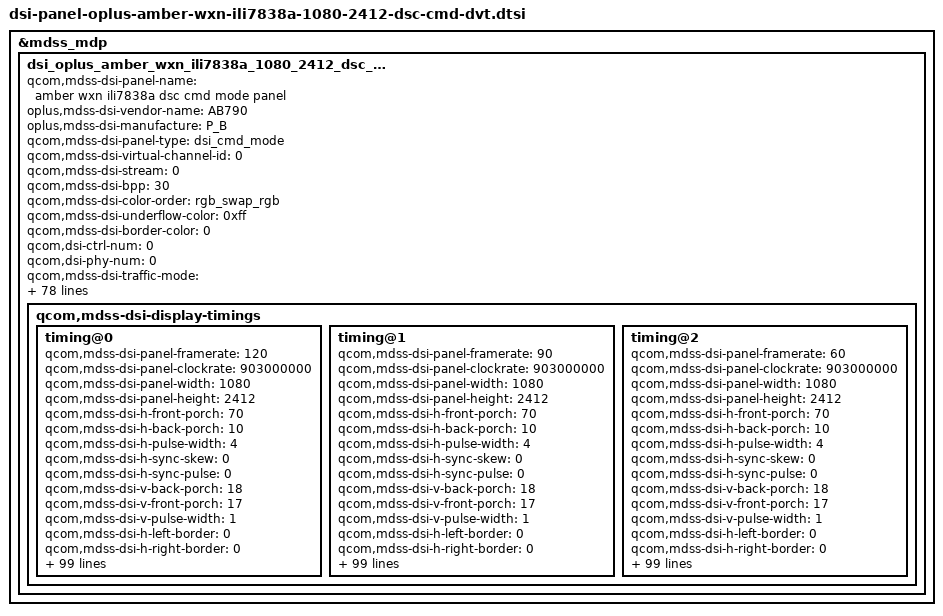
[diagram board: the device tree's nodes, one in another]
&mdss_mdp {
	dsi_oplus_amber_wxn_ili7838a_1080_2412_dsc_cmd_dvt: qcom,mdss_dsi_oplus_amber_wxn_ili7838a_1080_2412_dsc_cmd_dvt {
		qcom,mdss-dsi-panel-name = "amber wxn ili7838a dsc cmd mode panel";
		oplus,mdss-dsi-vendor-name = "AB790";
		oplus,mdss-dsi-manufacture = "P_B";
		qcom,mdss-dsi-panel-type = "dsi_cmd_mode";
		qcom,mdss-dsi-virtual-channel-id = <0>;
		qcom,mdss-dsi-stream = <0>;
		qcom,mdss-dsi-bpp = <30>;
		qcom,mdss-dsi-color-order = "rgb_swap_rgb";
		qcom,mdss-dsi-underflow-color = <0xff>;
		qcom,mdss-dsi-border-color = <0>;
		qcom,dsi-ctrl-num = <0>;
		qcom,dsi-phy-num = <0>;
		qcom,mdss-dsi-traffic-mode = "non_burst_sync_event";
		qcom,mdss-dsi-lane-map = "lane_map_0123";
		qcom,mdss-dsi-bllp-eof-power-mode;
		qcom,mdss-dsi-bllp-power-mode;
		qcom,mdss-dsi-lane-0-state;
		qcom,mdss-dsi-lane-1-state;
		qcom,mdss-dsi-lane-2-state;
		qcom,mdss-dsi-lane-3-state;
		qcom,mdss-dsi-dma-trigger = "trigger_sw";
		qcom,mdss-dsi-mdp-trigger = "none";
		qcom,mdss-dsi-reset-sequence = <1 10>, <0 10>, <1 10>;

		qcom,mdss-dsi-te-pin-select = <1>;
		qcom,mdss-dsi-te-dcs-command = <1>;
		qcom,mdss-dsi-te-check-enable;
		qcom,mdss-dsi-te-using-te-pin;
		qcom,mdss-dsi-lp11-init;
		qcom,mdss-dsi-wr-mem-start = <0x2c>;
		qcom,mdss-dsi-wr-mem-continue = <0x3c>;
		qcom,mdss-dsi-panel-hdr-enabled;
		qcom,mdss-dsi-panel-hdr-color-primaries = <15635 16450 34000 16000 13250 34500 7500 3000>;
		qcom,mdss-dsi-panel-peak-brightness = <5400000>;
		qcom,mdss-dsi-panel-blackness-level = <2000>;
		qcom,mdss-pan-physical-width-dimension = <70>;
		qcom,mdss-pan-physical-height-dimension = <155>;
		qcom,esd-check-enabled;
		qcom,mdss-dsi-panel-status-check-mode = "reg_read";
		qcom,mdss-dsi-panel-status-command = [06 01 00 01 05 00 01 0A];
		qcom,mdss-dsi-panel-status-command-state = "dsi_lp_mode";
		qcom,mdss-dsi-panel-status-value = <0x9C>;
		qcom,mdss-dsi-panel-status-read-length = <1>;
		qcom,mdss-dsi-dma-schedule-line = <1>;
		qcom,mdss-dsi-dma-schedule-window = <10>;
		qcom,mdss-dsi-display-timings {
			timing@0 {
				qcom,mdss-dsi-panel-framerate = <120>;
				qcom,mdss-dsi-panel-clockrate = <903000000>;
				qcom,mdss-dsi-panel-width = <1080>;
				qcom,mdss-dsi-panel-height = <2412>;
				qcom,mdss-dsi-h-front-porch = <70>;
				qcom,mdss-dsi-h-back-porch = <10>;
				qcom,mdss-dsi-h-pulse-width = <4>;
				qcom,mdss-dsi-h-sync-skew = <0>;
				qcom,mdss-dsi-h-sync-pulse = <0>;
				qcom,mdss-dsi-v-back-porch = <18>;
				qcom,mdss-dsi-v-front-porch = <17>;
				qcom,mdss-dsi-v-pulse-width = <1>;
				qcom,mdss-dsi-h-left-border = <0>;
				qcom,mdss-dsi-h-right-border = <0>;
				qcom,mdss-dsi-v-top-border = <0>;
				qcom,mdss-dsi-v-bottom-border = <0>;
				qcom,mdss-dsi-panel-jitter = <0x4 0x1>;
				qcom,mdss-mdp-transfer-time-us = <6727>;

				oplus,fod-on-vblank = <0>;
				oplus,fod-off-vblank = <0>;
				oplus,ofp-need-to-sync-data-in-aod-unlocking;
				oplus,ofp-aod-off-insert-black-frame = <1>;
				oplus,ofp-aod-off-black-frame-total-time = <42>;

				qcom,mdss-dsi-timing-switch-command = [
					//120HZ
					39 00 00 40 00 00 04 FF 78 38 02
					39 00 00 40 00 00 02 38 11
					39 00 00 00 00 00 04 FF 78 38 00
				];
				qcom,mdss-dsi-on-command = [
					39 01 00 00 00 00 04 FF 78 38 08
					39 01 00 00 00 00 02 45 4C
					39 01 00 00 00 00 04 FF 78 38 02
					39 01 00 00 00 00 02 38 11
					39 01 00 00 00 00 04 FF 78 38 00
					39 01 00 00 00 00 02 35 00
					39 01 00 00 00 00 02 53 20
					39 01 00 00 00 00 03 51 00 00
					39 01 00 00 00 00 02 95 10
					39 01 00 00 00 00 04 FF 78 38 00
					//dsc 10bit
					39 01 00 00 00 00 04 FF 78 38 07
					39 01 00 00 00 00 02 29 01
					39 01 00 00 00 00 64 20 00 00 00
						00 00 12 00 00 ab 30 a0 09 6c 04
						38 00 0c 02 1c 02 a3 01 9a 01 d8
						00 19 01 03 00 0a 00 0c 08 bb 0a
						5f 16 00 10 ec 07 10 20 00 06 0f
						0f 33 0e 1c 2a 38 46 54 62 69 70
						77 79 7b 7d 7e 01 c2 22 00 2a 40
						32 be 3a fc 3a fa 3a f8 3b 38 3b
						78 3b 76 4b b6 4b b6 4b f4 5b f4
						7c 34 00 00 00 00 00 00
					39 01 00 00 00 00 04 FF 78 38 07
					39 01 00 00 00 00 64 1F 00 00 00
						00 00 12 00 00 ab 30 a0 09 6c 04
						38 00 0c 02 1c 02 a3 01 9a 01 d8
						00 19 01 03 00 0a 00 0c 08 bb 0a
						5f 16 00 10 ec 07 10 20 00 06 0f
						0f 33 0e 1c 2a 38 46 54 62 69 70
						77 79 7b 7d 7e 01 c2 22 00 2a 40
						32 be 3a fc 3a fa 3a f8 3b 38 3b
						78 3b 76 4b b6 4b b6 4b f4 5b f4
						7c 34 00 00 00 00 00 00
					//lvd
					39 01 00 00 00 00 04 FF 78 38 1C
					39 01 00 00 00 00 02 78 10
					39 01 00 00 00 00 02 6A FF
					39 01 00 00 00 00 02 6E FF
					39 01 00 00 00 00 04 FF 78 38 02
					39 01 00 00 00 00 02 0A 20
					39 01 00 00 00 00 04 FF 78 38 05
					39 01 00 00 00 00 02 01 50
					39 01 00 00 00 00 02 1D DF
					39 01 00 00 00 00 02 1E 07
					//Sleep out
					39 00 00 40 00 00 04 FF 78 38 07
					15 00 00 40 00 00 02 2B 24
					39 01 00 00 00 00 04 FF 78 38 00
					05 01 00 00 79 00 01 11
					39 01 00 00 00 00 04 FF 78 38 05
					39 01 00 00 00 00 02 5B 42
					39 01 00 00 00 00 04 FF 78 38 08
					39 01 00 00 00 00 02 57 25
					39 01 00 00 00 00 04 FF 78 38 06
					39 01 00 00 00 00 02 C6 01
					39 01 00 00 00 00 04 FF 78 38 00
					05 01 00 00 46 00 01 29
				];
				qcom,mdss-dsi-off-command= [
					05 01 00 00 15 00 01 28
					05 01 00 00 79 00 01 10
				];
				qcom,mdss-dsi-post-on-backlight = [
					/* Display On */
					//39 00 00 40 00 00 04 FF 78 38 00
					//05 00 00 00 00 00 01 39
				];
				qcom,mdss-dsi-panel-info-switch-page-command = [
					/*read panel info switch page 0f*/
					39 00 00 00 00 00 04 FF 78 38 0F
				];
				qcom,mdss-dsi-default-switch-page-command = [
					/*switch default page*/
					39 00 00 00 00 00 04 FF 78 38 00
				];
				qcom,mdss-dsi-hbm-on-command = [
					//hbm
					39 00 00 40 00 00 04 FF 78 38 0B
					39 00 00 40 00 00 02 17 E2
					39 00 00 40 00 00 02 18 E2
					39 00 00 40 00 00 02 19 E2
					39 00 00 40 00 00 02 1A E2
					39 00 00 40 00 00 02 1B E2
					39 00 00 40 00 00 02 1C E2
					39 00 00 40 00 00 02 1D E2
					39 00 00 40 00 00 04 FF 78 38 0A
					39 00 00 40 00 00 02 37 4F
					39 00 00 40 00 00 02 38 B4
					39 00 00 40 00 00 04 FF 78 38 00
					39 00 00 40 00 00 02 55 00
					39 00 00 40 00 00 04 FF 78 38 05
					39 00 00 40 00 00 02 4F 24
					39 00 00 40 00 00 04 FF 78 38 00
					39 00 00 40 09 00 02 53 20
					39 00 00 40 00 00 03 51 0E 4C
					39 00 00 00 00 00 04 FF 78 38 00
				];
				qcom,mdss-dsi-normal-hbm-on-command = [
					//hbm
				];
				qcom,mdss-dsi-hbm-off-command = [
					39 00 00 40 00 00 04 FF 78 38 0A
					39 00 00 40 00 00 02 37 4F
					39 00 00 40 00 00 02 38 48
					39 00 00 40 00 00 04 FF 78 38 00
					39 00 00 40 00 00 02 55 00
					39 00 00 40 00 00 03 51 0D BB
					39 00 00 40 00 00 04 FF 78 38 00
					39 00 00 40 00 00 04 FF 78 38 05
					39 00 00 40 00 00 02 4F 2C
					39 00 00 00 00 00 04 FF 78 38 00
				];
				qcom,mdss-dsi-lhbm-on-command = [
					39 00 00 60 00 00 04 FF 78 38 05
					15 00 00 60 00 00 02 5D 1E
					39 00 00 60 00 00 04 FF 78 38 0D
					15 00 00 60 00 00 02 08 51
					15 00 00 60 00 00 02 65 2D
					15 00 00 60 00 00 02 47 E9
					15 00 00 60 00 00 02 48 E9
					15 00 00 60 00 00 02 49 E9
					39 00 00 60 00 00 04 FF 78 38 0C
					15 00 00 60 00 00 02 AB AB
					39 00 00 60 00 00 04 FF 78 38 00
					15 00 00 60 00 00 02 95 11
					39 00 00 60 00 00 04 FF 78 38 0A
					15 00 00 60 00 00 02 1C 11
					15 00 00 60 00 00 02 1D 8A
					15 00 00 60 00 00 02 1E 8A
					39 00 00 20 00 00 04 FF 78 38 00
				];
				qcom,mdss-dsi-lhbm-on2-command = [
					39 00 00 60 00 00 04 FF 78 38 0A
					15 00 00 60 00 00 02 1C 88
					15 00 00 60 00 00 02 1D 00
					15 00 00 60 00 00 02 1E 00
					39 00 00 20 00 00 04 FF 78 38 00
				];
				qcom,mdss-dsi-lhbm-off-command = [
					39 00 00 60 00 00 04 FF 78 38 0D
					15 00 00 60 00 00 02 08 D1
					15 00 00 60 00 00 02 65 00
					39 00 00 60 00 00 04 FF 78 38 05
					15 00 00 60 00 00 02 5D 42
					39 00 00 60 00 00 04 FF 78 38 00
					15 00 00 60 00 00 02 95 10
					39 00 00 60 00 00 04 FF 78 38 0A
					15 00 00 60 00 00 02 1C 88
					15 00 00 60 00 00 02 1D 00
					15 00 00 60 00 00 02 1E 00
					15 00 00 60 00 00 02 1F 88
					15 00 00 60 00 00 02 20 00
					15 00 00 60 00 00 02 21 00
					15 00 00 60 00 00 02 22 88
					15 00 00 60 00 00 02 23 00
					15 00 00 60 00 00 02 24 00
					39 00 00 20 00 00 04 FF 78 38 00
				];
				qcom,mdss-dsi-lhbm-off2-command = [
					39 00 00 60 00 00 04 FF 78 38 0A
					15 00 00 60 00 00 02 1C 88
					15 00 00 60 00 00 02 1D 00
					15 00 00 60 00 00 02 1E 00
					15 00 00 60 00 00 02 1F 40
					15 00 00 60 00 00 02 20 00
					15 00 00 60 00 00 02 21 77
					15 00 00 60 00 00 02 22 00
					15 00 00 60 00 00 02 23 03
					15 00 00 60 00 00 02 24 00
					39 00 00 20 00 00 04 FF 78 38 00
				];
				qcom,mdss-dsi-aod-hbm-on-command = [

				];
				qcom,mdss-dsi-aod-hbm-off-command = [

				];
				qcom,mdss-dsi-aod-high-mode-command = [
					39 00 00 40 00 00 04 FF 78 38 02
					15 00 00 40 00 00 02 38 11
					15 00 00 40 00 00 02 19 02
					39 00 00 40 00 00 04 FF 78 38 00
					05 00 00 00 00 00 01 39
				];
				qcom,mdss-dsi-aod-low-mode-command = [
					39 00 00 40 00 00 04 FF 78 38 02
					15 00 00 40 00 00 02 38 21
					15 00 00 40 00 00 02 19 01
					39 00 00 40 00 00 04 FF 78 38 00
					05 00 00 00 00 00 01 39
				];
				qcom,mdss-dsi-lp1-command = [
					//AOD ON
					39 00 00 40 00 00 04 FF 78 38 02
					15 00 00 40 00 00 02 38 11
					15 00 00 40 00 00 02 19 02
					39 00 00 40 00 00 04 FF 78 38 00
					05 00 00 00 00 00 01 39
				];
				qcom,mdss-dsi-nolp-command = [
					//AOD OFF
					39 00 00 40 00 00 04 FF 78 38 00
					05 00 00 40 00 00 01 38
					39 00 00 40 00 00 03 51 00 00
					39 01 00 40 00 00 04 FF 78 38 05
					39 01 00 40 00 00 02 5B 42
					39 00 00 00 00 00 04 FF 78 38 00
				];
				//qcom,mdss-dsi-seed-off-command = [

				//];
				//qcom,mdss-dsi-seed-3-command = [

				//];
				//qcom,mdss-dsi-seed-2-command = [

				//];
				//qcom,mdss-dsi-seed-1-command = [

				//];
				//qcom,mdss-dsi-seed-0-command = [

				//];
				qcom,mdss-dsi-hbm-enter-switch-command = [
					39 00 00 00 00 00 03 51 0D BB
				];
				qcom,mdss-dsi-hbm-exit-switch-command = [
					39 00 00 00 00 00 03 51 0D BB
				];
				qcom,mdss-dsi-osc-clk-mode0-command = [
				];
				qcom,mdss-dsi-osc-clk-mode1-command = [
				];
				qcom,mdss-dsi-ffc-mode0-command = [
					/* osc 121.5 */
					39 00 00 40 00 00 04 FF 78 38 0F
					39 00 00 40 00 00 02 6E 12
					39 00 00 00 00 00 04 FF 78 38 00
				];
				qcom,mdss-dsi-ffc-mode1-command = [
					/* osc 128 */
					39 00 00 40 00 00 04 FF 78 38 0F
					39 00 00 40 00 00 02 6E 13
					39 00 00 00 00 00 04 FF 78 38 00
				];
				qcom,mdss-dsi-timing-switch-command-state = "dsi_lp_mode";
				qcom,mdss-dsi-on-command-state = "dsi_lp_mode";
				qcom,mdss-dsi-panel-info-switch-page-command-state = "dsi_lp_mode";
				qcom,mdss-dsi-default-switch-page-command-state = "dsi_lp_mode";
				qcom,mdss-dsi-off-command-state = "dsi_lp_mode";
				qcom,mdss-dsi-hbm-on-command-state = "dsi_lp_mode";
				qcom,mdss-dsi-hbm-off-command-state = "dsi_lp_mode";
				qcom,mdss-dsi-lhbm-on-command-state = "dsi_hs_mode";
				qcom,mdss-dsi-lhbm-off-command-state = "dsi_hs_mode";
				qcom,mdss-dsi-lhbm-on2-command-state = "dsi_hs_mode";
				qcom,mdss-dsi-lhbm-off2-command-state = "dsi_hs_mode";
				qcom,mdss-dsi-lp1-command-state = "dsi_lp_mode";
				qcom,mdss-dsi-nolp-command-state = "dsi_lp_mode";
				qcom,mdss-dsi-aod-high-mode-command-state = "dsi_lp_mode";
				qcom,mdss-dsi-aod-low-mode-command-state = "dsi_lp_mode";
				qcom,mdss-dsi-osc-clk-mode0-command-state = "dsi_lp_mode";
				qcom,mdss-dsi-osc-clk-mode1-command-state = "dsi_lp_mode";
				qcom,mdss-dsi-ffc-mode0-command-state = "dsi_lp_mode";
				qcom,mdss-dsi-ffc-mode1-command-state = "dsi_lp_mode";
				//qcom,mdss-dsi-seed-0-command-state = "dsi_lp_mode";
				//qcom,mdss-dsi-seed-1-command-state = "dsi_lp_mode";
				//qcom,mdss-dsi-seed-2-command-state = "dsi_lp_mode";
				//qcom,mdss-dsi-seed-3-command-state = "dsi_lp_mode";
				//qcom,mdss-dsi-seed-off-command-state = "dsi_lp_mode";
				qcom,compression-mode = "dsc";
				qcom,mdss-dsc-slice-height = <12>;
				qcom,mdss-dsc-slice-width = <540>;
				qcom,mdss-dsc-slice-per-pkt = <2>;
				qcom,mdss-dsc-bit-per-component = <10>;
				qcom,mdss-dsc-bit-per-pixel = <10>;
				qcom,mdss-dsc-block-prediction-enable;
				qcom,mdss-dsc-version = <0x12>;
			};
			timing@1 {
				qcom,mdss-dsi-panel-framerate = <90>;
				qcom,mdss-dsi-panel-clockrate = <903000000>;
				qcom,mdss-dsi-panel-width = <1080>;
				qcom,mdss-dsi-panel-height = <2412>;
				qcom,mdss-dsi-h-front-porch = <70>;
				qcom,mdss-dsi-h-back-porch = <10>;
				qcom,mdss-dsi-h-pulse-width = <4>;
				qcom,mdss-dsi-h-sync-skew = <0>;
				qcom,mdss-dsi-h-sync-pulse = <0>;
				qcom,mdss-dsi-v-back-porch = <18>;
				qcom,mdss-dsi-v-front-porch = <17>;
				qcom,mdss-dsi-v-pulse-width = <1>;
				qcom,mdss-dsi-h-left-border = <0>;
				qcom,mdss-dsi-h-right-border = <0>;
				qcom,mdss-dsi-v-top-border = <0>;
				qcom,mdss-dsi-v-bottom-border = <0>;
				qcom,mdss-dsi-panel-jitter = <0x4 0x1>;
				qcom,mdss-mdp-transfer-time-us = <9000>;

				oplus,fod-on-vblank = <0>;
				oplus,fod-off-vblank = <0>;
				oplus,ofp-need-to-sync-data-in-aod-unlocking;
				oplus,ofp-aod-off-insert-black-frame = <1>;
				oplus,ofp-aod-off-black-frame-total-time = <45>;
				qcom,mdss-dsi-timing-switch-command = [
					//90HZ
					39 00 00 40 00 00 04 FF 78 38 02
					39 00 00 40 00 00 02 38 12
					39 00 00 00 00 00 04 FF 78 38 00
				];
				qcom,mdss-dsi-on-command = [
					39 01 00 00 00 00 04 FF 78 38 08
					39 01 00 00 00 00 02 45 4C
					39 01 00 00 00 00 04 FF 78 38 02
					39 01 00 00 00 00 02 38 12
					39 01 00 00 00 00 04 FF 78 38 00
					39 01 00 00 00 00 02 35 00
					39 01 00 00 00 00 02 53 20
					39 01 00 00 00 00 03 51 00 00
					39 01 00 00 00 00 02 95 10
					39 01 00 00 00 00 04 FF 78 38 00
					//dsc 10bit
					39 01 00 00 00 00 04 FF 78 38 07
					39 01 00 00 00 00 02 29 01
					39 01 00 00 00 00 64 20 00 00 00
						00 00 12 00 00 ab 30 a0 09 6c 04
						38 00 0c 02 1c 02 a3 01 9a 01 d8
						00 19 01 03 00 0a 00 0c 08 bb 0a
						5f 16 00 10 ec 07 10 20 00 06 0f
						0f 33 0e 1c 2a 38 46 54 62 69 70
						77 79 7b 7d 7e 01 c2 22 00 2a 40
						32 be 3a fc 3a fa 3a f8 3b 38 3b
						78 3b 76 4b b6 4b b6 4b f4 5b f4
						7c 34 00 00 00 00 00 00
					39 01 00 00 00 00 04 FF 78 38 07
					39 01 00 00 00 00 64 1F 00 00 00
						00 00 12 00 00 ab 30 a0 09 6c 04
						38 00 0c 02 1c 02 a3 01 9a 01 d8
						00 19 01 03 00 0a 00 0c 08 bb 0a
						5f 16 00 10 ec 07 10 20 00 06 0f
						0f 33 0e 1c 2a 38 46 54 62 69 70
						77 79 7b 7d 7e 01 c2 22 00 2a 40
						32 be 3a fc 3a fa 3a f8 3b 38 3b
						78 3b 76 4b b6 4b b6 4b f4 5b f4
						7c 34 00 00 00 00 00 00
					//lvd
					39 01 00 00 00 00 04 FF 78 38 1C
					39 01 00 00 00 00 02 78 10
					39 01 00 00 00 00 02 6A FF
					39 01 00 00 00 00 02 6E FF
					39 01 00 00 00 00 04 FF 78 38 02
					39 01 00 00 00 00 02 0A 20
					39 01 00 00 00 00 04 FF 78 38 05
					39 01 00 00 00 00 02 01 50
					39 01 00 00 00 00 02 1D DF
					39 01 00 00 00 00 02 1E 07
					//Sleep out
					39 00 00 40 00 00 04 FF 78 38 07
					15 00 00 40 00 00 02 2B 24
					39 01 00 00 00 00 04 FF 78 38 00
					05 01 00 00 79 00 01 11
					39 01 00 00 00 00 04 FF 78 38 05
					39 01 00 00 00 00 02 5B 42
					39 01 00 00 00 00 04 FF 78 38 08
					39 01 00 00 00 00 02 57 25
					39 01 00 00 00 00 04 FF 78 38 06
					39 01 00 00 00 00 02 C6 01
					39 01 00 00 00 00 04 FF 78 38 00
					05 01 00 00 46 00 01 29
				];
				qcom,mdss-dsi-off-command= [
					05 01 00 00 15 00 01 28
					05 01 00 00 79 00 01 10
				];
				qcom,mdss-dsi-post-on-backlight = [
					/* Display On */
					//39 00 00 40 00 00 04 FF 78 38 00
					//05 00 00 00 00 00 01 39
				];
				qcom,mdss-dsi-panel-info-switch-page-command = [
					/*read panel info switch page 0f*/
					39 00 00 00 00 00 04 FF 78 38 0F
				];
				qcom,mdss-dsi-default-switch-page-command = [
					/*switch default page*/
					39 00 00 00 00 00 04 FF 78 38 00
				];
				qcom,mdss-dsi-hbm-on-command = [
					//hbm
					39 00 00 40 00 00 04 FF 78 38 0B
					39 00 00 40 00 00 02 17 E2
					39 00 00 40 00 00 02 18 E2
					39 00 00 40 00 00 02 19 E2
					39 00 00 40 00 00 02 1A E2
					39 00 00 40 00 00 02 1B E2
					39 00 00 40 00 00 02 1C E2
					39 00 00 40 00 00 02 1D E2
					39 00 00 40 00 00 04 FF 78 38 0A
					39 00 00 40 00 00 02 37 4F
					39 00 00 40 00 00 02 38 B4
					39 00 00 40 00 00 04 FF 78 38 00
					39 00 00 40 00 00 02 55 00
					39 00 00 40 00 00 04 FF 78 38 05
					39 00 00 40 00 00 02 4F 24
					39 00 00 40 00 00 04 FF 78 38 00
					39 00 00 40 0C 00 02 53 20
					39 00 00 40 00 00 03 51 0E 4C
					39 00 00 00 00 00 04 FF 78 38 00
				];
				qcom,mdss-dsi-normal-hbm-on-command = [
					//hbm
				];
				qcom,mdss-dsi-hbm-off-command = [
					39 00 00 40 00 00 04 FF 78 38 0A
					39 00 00 40 00 00 02 37 4F
					39 00 00 40 00 00 02 38 48
					39 00 00 40 00 00 04 FF 78 38 00
					39 00 00 40 00 00 02 55 00
					39 00 00 40 00 00 03 51 0D BB
					39 00 00 40 00 00 04 FF 78 38 00
					39 00 00 40 00 00 04 FF 78 38 05
					39 00 00 40 00 00 02 4F 2C
					39 00 00 00 00 00 04 FF 78 38 00
				];
				qcom,mdss-dsi-lhbm-on-command = [
					39 00 00 60 00 00 04 FF 78 38 05
					15 00 00 60 00 00 02 5D 1E
					39 00 00 60 00 00 04 FF 78 38 0D
					15 00 00 60 00 00 02 08 51
					15 00 00 60 00 00 02 65 2D
					15 00 00 60 00 00 02 47 E9
					15 00 00 60 00 00 02 48 E9
					15 00 00 60 00 00 02 49 E9
					39 00 00 60 00 00 04 FF 78 38 0C
					15 00 00 60 00 00 02 AB AB
					39 00 00 60 00 00 04 FF 78 38 00
					15 00 00 60 00 00 02 95 11
					39 00 00 60 00 00 04 FF 78 38 0A
					15 00 00 60 00 00 02 1C 11
					15 00 00 60 00 00 02 1D 8A
					15 00 00 60 00 00 02 1E 8A
					39 00 00 20 00 00 04 FF 78 38 00
				];
				qcom,mdss-dsi-lhbm-on2-command = [
					39 00 00 60 00 00 04 FF 78 38 0A
					15 00 00 60 00 00 02 1C 88
					15 00 00 60 00 00 02 1D 00
					15 00 00 60 00 00 02 1E 00
					39 00 00 20 00 00 04 FF 78 38 00
				];
				qcom,mdss-dsi-lhbm-off-command = [
					39 00 00 60 00 00 04 FF 78 38 0D
					15 00 00 60 00 00 02 08 D1
					15 00 00 60 00 00 02 65 00
					39 00 00 60 00 00 04 FF 78 38 05
					15 00 00 60 00 00 02 5D 42
					39 00 00 60 00 00 04 FF 78 38 00
					15 00 00 60 00 00 02 95 10
					39 00 00 60 00 00 04 FF 78 38 0A
					15 00 00 60 00 00 02 1C 88
					15 00 00 60 00 00 02 1D 00
					15 00 00 60 00 00 02 1E 00
					15 00 00 60 00 00 02 1F 88
					15 00 00 60 00 00 02 20 00
					15 00 00 60 00 00 02 21 00
					15 00 00 60 00 00 02 22 88
					15 00 00 60 00 00 02 23 00
					15 00 00 60 00 00 02 24 00
					39 00 00 20 00 00 04 FF 78 38 00
				];
				qcom,mdss-dsi-lhbm-off2-command = [
					39 00 00 60 00 00 04 FF 78 38 0A
					15 00 00 60 00 00 02 1C 88
					15 00 00 60 00 00 02 1D 00
					15 00 00 60 00 00 02 1E 00
					15 00 00 60 00 00 02 1F 40
					15 00 00 60 00 00 02 20 00
					15 00 00 60 00 00 02 21 77
					15 00 00 60 00 00 02 22 00
					15 00 00 60 00 00 02 23 03
					15 00 00 60 00 00 02 24 00
					39 00 00 20 00 00 04 FF 78 38 00
				];
				qcom,mdss-dsi-aod-hbm-on-command = [

				];
				qcom,mdss-dsi-aod-hbm-off-command = [

				];
				qcom,mdss-dsi-aod-high-mode-command = [
					39 00 00 40 00 00 04 FF 78 38 02
					15 00 00 40 00 00 02 38 12
					15 00 00 40 00 00 02 19 02
					39 00 00 40 00 00 04 FF 78 38 00
					05 00 00 00 00 00 01 39
				];
				qcom,mdss-dsi-aod-low-mode-command = [
					39 00 00 40 00 00 04 FF 78 38 02
					15 00 00 40 00 00 02 38 22
					15 00 00 40 00 00 02 19 01
					39 00 00 40 00 00 04 FF 78 38 00
					05 00 00 00 00 00 01 39
				];
				qcom,mdss-dsi-lp1-command = [
					//AOD ON
					39 00 00 40 00 00 04 FF 78 38 02
					15 00 00 40 00 00 02 38 12
					15 00 00 40 00 00 02 19 02
					39 00 00 40 00 00 04 FF 78 38 00
					05 00 00 00 00 00 01 39
				];
				qcom,mdss-dsi-nolp-command = [
					//AOD OFF
					39 00 00 40 00 00 04 FF 78 38 00
					05 00 00 40 00 00 01 38
					39 00 00 40 00 00 03 51 00 00
					39 01 00 40 00 00 04 FF 78 38 05
					39 01 00 40 00 00 02 5B 42
					39 00 00 00 00 00 04 FF 78 38 00
				];
				//qcom,mdss-dsi-seed-off-command = [

				//];
				//qcom,mdss-dsi-seed-3-command = [

				//];
				//qcom,mdss-dsi-seed-2-command = [

				//];
				//qcom,mdss-dsi-seed-1-command = [

				//];
				//qcom,mdss-dsi-seed-0-command = [

				//];
				qcom,mdss-dsi-hbm-enter-switch-command = [
					39 00 00 00 00 00 03 51 0D BB
				];
				qcom,mdss-dsi-hbm-exit-switch-command = [
					39 00 00 00 00 00 03 51 0D BB
				];
				qcom,mdss-dsi-osc-clk-mode0-command = [
				];
				qcom,mdss-dsi-osc-clk-mode1-command = [
				];
				qcom,mdss-dsi-ffc-mode0-command = [
					/* osc 121.5 */
					39 00 00 40 00 00 04 FF 78 38 0F
					39 00 00 40 00 00 02 6E 12
					39 00 00 00 00 00 04 FF 78 38 00
				];
				qcom,mdss-dsi-ffc-mode1-command = [
					/* osc 128 */
					39 00 00 40 00 00 04 FF 78 38 0F
					39 00 00 40 00 00 02 6E 13
					39 00 00 00 00 00 04 FF 78 38 00
				];
				qcom,mdss-dsi-timing-switch-command-state = "dsi_lp_mode";
				qcom,mdss-dsi-on-command-state = "dsi_lp_mode";
				qcom,mdss-dsi-panel-info-switch-page-command-state = "dsi_lp_mode";
				qcom,mdss-dsi-default-switch-page-command-state = "dsi_lp_mode";
				qcom,mdss-dsi-off-command-state = "dsi_lp_mode";
				qcom,mdss-dsi-hbm-on-command-state = "dsi_lp_mode";
				qcom,mdss-dsi-hbm-off-command-state = "dsi_lp_mode";
				qcom,mdss-dsi-lhbm-on-command-state = "dsi_hs_mode";
				qcom,mdss-dsi-lhbm-off-command-state = "dsi_hs_mode";
				qcom,mdss-dsi-lhbm-on2-command-state = "dsi_hs_mode";
				qcom,mdss-dsi-lhbm-off2-command-state = "dsi_hs_mode";
				qcom,mdss-dsi-lp1-command-state = "dsi_lp_mode";
				qcom,mdss-dsi-nolp-command-state = "dsi_lp_mode";
				qcom,mdss-dsi-aod-high-mode-command-state = "dsi_lp_mode";
				qcom,mdss-dsi-aod-low-mode-command-state = "dsi_lp_mode";
				qcom,mdss-dsi-osc-clk-mode0-command-state = "dsi_lp_mode";
				qcom,mdss-dsi-osc-clk-mode1-command-state = "dsi_lp_mode";
				qcom,mdss-dsi-ffc-mode0-command-state = "dsi_lp_mode";
				qcom,mdss-dsi-ffc-mode1-command-state = "dsi_lp_mode";
				//qcom,mdss-dsi-seed-0-command-state = "dsi_lp_mode";
				//qcom,mdss-dsi-seed-1-command-state = "dsi_lp_mode";
				//qcom,mdss-dsi-seed-2-command-state = "dsi_lp_mode";
				//qcom,mdss-dsi-seed-3-command-state = "dsi_lp_mode";
				//qcom,mdss-dsi-seed-off-command-state = "dsi_lp_mode";
				qcom,compression-mode = "dsc";
				qcom,mdss-dsc-slice-height = <12>;
				qcom,mdss-dsc-slice-width = <540>;
				qcom,mdss-dsc-slice-per-pkt = <2>;
				qcom,mdss-dsc-bit-per-component = <10>;
				qcom,mdss-dsc-bit-per-pixel = <10>;
				qcom,mdss-dsc-block-prediction-enable;
				qcom,mdss-dsc-version = <0x12>;
			};
			timing@2 {
				qcom,mdss-dsi-panel-framerate = <60>;
				qcom,mdss-dsi-panel-clockrate = <903000000>;
				qcom,mdss-dsi-panel-width = <1080>;
				qcom,mdss-dsi-panel-height = <2412>;
				qcom,mdss-dsi-h-front-porch = <70>;
				qcom,mdss-dsi-h-back-porch = <10>;
				qcom,mdss-dsi-h-pulse-width = <4>;
				qcom,mdss-dsi-h-sync-skew = <0>;
				qcom,mdss-dsi-h-sync-pulse = <0>;
				qcom,mdss-dsi-v-back-porch = <18>;
				qcom,mdss-dsi-v-front-porch = <17>;
				qcom,mdss-dsi-v-pulse-width = <1>;
				qcom,mdss-dsi-h-left-border = <0>;
				qcom,mdss-dsi-h-right-border = <0>;
				qcom,mdss-dsi-v-top-border = <0>;
				qcom,mdss-dsi-v-bottom-border = <0>;
				qcom,mdss-dsi-panel-jitter = <0x4 0x1>;
				qcom,mdss-mdp-transfer-time-us = <12000>;

				oplus,fod-on-vblank = <0>;
				oplus,fod-off-vblank = <0>;
				oplus,ofp-need-to-sync-data-in-aod-unlocking;
				oplus,ofp-aod-off-insert-black-frame = <2>;
				oplus,ofp-aod-off-black-frame-total-time = <59>;

				qcom,mdss-dsi-timing-switch-command = [
					//60HZ
					39 00 00 40 00 00 04 FF 78 38 02
					39 00 00 40 00 00 02 38 13
					39 00 00 00 00 00 04 FF 78 38 00
				];
				qcom,mdss-dsi-on-command = [
					39 01 00 00 00 00 04 FF 78 38 08
					39 01 00 00 00 00 02 45 4C
					39 01 00 00 00 00 04 FF 78 38 02
					39 01 00 00 00 00 02 38 13
					39 01 00 00 00 00 04 FF 78 38 00
					39 01 00 00 00 00 02 35 00
					39 01 00 00 00 00 02 53 20
					39 01 00 00 00 00 03 51 00 00
					39 01 00 00 00 00 02 95 10
					39 01 00 00 00 00 04 FF 78 38 00
					//dsc 10bit
					39 01 00 00 00 00 04 FF 78 38 07
					39 01 00 00 00 00 02 29 01
					39 01 00 00 00 00 64 20 00 00 00
						00 00 12 00 00 ab 30 a0 09 6c 04
						38 00 0c 02 1c 02 a3 01 9a 01 d8
						00 19 01 03 00 0a 00 0c 08 bb 0a
						5f 16 00 10 ec 07 10 20 00 06 0f
						0f 33 0e 1c 2a 38 46 54 62 69 70
						77 79 7b 7d 7e 01 c2 22 00 2a 40
						32 be 3a fc 3a fa 3a f8 3b 38 3b
						78 3b 76 4b b6 4b b6 4b f4 5b f4
						7c 34 00 00 00 00 00 00
					39 01 00 00 00 00 04 FF 78 38 07
					39 01 00 00 00 00 64 1F 00 00 00
						00 00 12 00 00 ab 30 a0 09 6c 04
						38 00 0c 02 1c 02 a3 01 9a 01 d8
						00 19 01 03 00 0a 00 0c 08 bb 0a
						5f 16 00 10 ec 07 10 20 00 06 0f
						0f 33 0e 1c 2a 38 46 54 62 69 70
						77 79 7b 7d 7e 01 c2 22 00 2a 40
						32 be 3a fc 3a fa 3a f8 3b 38 3b
						78 3b 76 4b b6 4b b6 4b f4 5b f4
						7c 34 00 00 00 00 00 00
					//lvd
					39 01 00 00 00 00 04 FF 78 38 1C
					39 01 00 00 00 00 02 78 10
					39 01 00 00 00 00 02 6A FF
					39 01 00 00 00 00 02 6E FF
					39 01 00 00 00 00 04 FF 78 38 02
					39 01 00 00 00 00 02 0A 20
					39 01 00 00 00 00 04 FF 78 38 05
					39 01 00 00 00 00 02 01 50
					39 01 00 00 00 00 02 1D DF
					39 01 00 00 00 00 02 1E 07
					//Sleep out
					39 00 00 40 00 00 04 FF 78 38 07
					15 00 00 40 00 00 02 2B 24
					39 01 00 00 00 00 04 FF 78 38 00
					05 01 00 00 79 00 01 11
					39 01 00 00 00 00 04 FF 78 38 05
					39 01 00 00 00 00 02 5B 42
					39 01 00 00 00 00 04 FF 78 38 08
					39 01 00 00 00 00 02 57 25
					39 01 00 00 00 00 04 FF 78 38 06
					39 01 00 00 00 00 02 C6 01
					39 01 00 00 00 00 04 FF 78 38 00
					05 01 00 00 46 00 01 29
				];
				qcom,mdss-dsi-off-command= [
					05 01 00 00 15 00 01 28
					05 01 00 00 79 00 01 10
				];
				qcom,mdss-dsi-post-on-backlight = [
					/* Display On */
					//39 00 00 40 00 00 04 FF 78 38 00
					//05 00 00 00 00 00 01 39
				];
				qcom,mdss-dsi-panel-info-switch-page-command = [
					/*read panel info switch page 0f*/
					39 00 00 00 00 00 04 FF 78 38 0F
				];
				qcom,mdss-dsi-default-switch-page-command = [
					/*switch default page*/
					39 00 00 00 00 00 04 FF 78 38 00
				];
				qcom,mdss-dsi-hbm-on-command = [
					//hbm
					39 00 00 40 00 00 04 FF 78 38 0B
					39 00 00 40 00 00 02 17 E2
					39 00 00 40 00 00 02 18 E2
					39 00 00 40 00 00 02 19 E2
					39 00 00 40 00 00 02 1A E2
					39 00 00 40 00 00 02 1B E2
					39 00 00 40 00 00 02 1C E2
					39 00 00 40 00 00 02 1D E2
					39 00 00 40 00 00 04 FF 78 38 0A
					39 00 00 40 00 00 02 37 4F
					39 00 00 40 00 00 02 38 B4
					39 00 00 40 00 00 04 FF 78 38 00
					39 00 00 40 00 00 02 55 00
					39 00 00 40 00 00 04 FF 78 38 05
					39 00 00 40 00 00 02 4F 24
					39 00 00 40 00 00 04 FF 78 38 00
					39 00 00 40 11 00 02 53 20
					39 00 00 40 00 00 03 51 0E 4C
					39 00 00 00 00 00 04 FF 78 38 00
				];
				qcom,mdss-dsi-normal-hbm-on-command = [
					//hbm
				];
				qcom,mdss-dsi-hbm-off-command = [
					39 00 00 40 00 00 04 FF 78 38 0A
					39 00 00 40 00 00 02 37 4F
					39 00 00 40 00 00 02 38 48
					39 00 00 40 00 00 04 FF 78 38 00
					39 00 00 40 00 00 02 55 00
					39 00 00 40 00 00 03 51 0D BB
					39 00 00 40 00 00 04 FF 78 38 00
					39 00 00 40 00 00 04 FF 78 38 05
					39 00 00 40 00 00 02 4F 2C
					39 00 00 00 00 00 04 FF 78 38 00
				];
				qcom,mdss-dsi-lhbm-on-command = [
					39 00 00 60 00 00 04 FF 78 38 05
					15 00 00 60 00 00 02 5D 1E
					39 00 00 60 00 00 04 FF 78 38 0D
					15 00 00 60 00 00 02 08 51
					15 00 00 60 00 00 02 65 2D
					15 00 00 60 00 00 02 47 E9
					15 00 00 60 00 00 02 48 E9
					15 00 00 60 00 00 02 49 E9
					39 00 00 60 00 00 04 FF 78 38 0C
					15 00 00 60 00 00 02 AB AB
					39 00 00 60 00 00 04 FF 78 38 00
					15 00 00 60 00 00 02 95 11
					39 00 00 60 00 00 04 FF 78 38 0A
					15 00 00 60 00 00 02 1C 11
					15 00 00 60 00 00 02 1D 8A
					15 00 00 60 00 00 02 1E 8A
					39 00 00 20 00 00 04 FF 78 38 00
				];
				qcom,mdss-dsi-lhbm-on2-command = [
					39 00 00 60 00 00 04 FF 78 38 0A
					15 00 00 60 00 00 02 1C 88
					15 00 00 60 00 00 02 1D 00
					15 00 00 60 00 00 02 1E 00
					39 00 00 20 00 00 04 FF 78 38 00
				];
				qcom,mdss-dsi-lhbm-off-command = [
					39 00 00 60 00 00 04 FF 78 38 0D
					15 00 00 60 00 00 02 08 D1
					15 00 00 60 00 00 02 65 00
					39 00 00 60 00 00 04 FF 78 38 05
					15 00 00 60 00 00 02 5D 42
					39 00 00 60 00 00 04 FF 78 38 00
					15 00 00 60 00 00 02 95 10
					39 00 00 60 00 00 04 FF 78 38 0A
					15 00 00 60 00 00 02 1C 88
					15 00 00 60 00 00 02 1D 00
					15 00 00 60 00 00 02 1E 00
					15 00 00 60 00 00 02 1F 88
					15 00 00 60 00 00 02 20 00
					15 00 00 60 00 00 02 21 00
					15 00 00 60 00 00 02 22 88
					15 00 00 60 00 00 02 23 00
					15 00 00 60 00 00 02 24 00
					39 00 00 20 00 00 04 FF 78 38 00
				];
				qcom,mdss-dsi-lhbm-off2-command = [
					39 00 00 60 00 00 04 FF 78 38 0A
					15 00 00 60 00 00 02 1C 88
					15 00 00 60 00 00 02 1D 00
					15 00 00 60 00 00 02 1E 00
					15 00 00 60 00 00 02 1F 40
					15 00 00 60 00 00 02 20 00
					15 00 00 60 00 00 02 21 77
					15 00 00 60 00 00 02 22 00
					15 00 00 60 00 00 02 23 03
					15 00 00 60 00 00 02 24 00
					39 00 00 20 00 00 04 FF 78 38 00
				];
				qcom,mdss-dsi-aod-hbm-on-command = [

				];
				qcom,mdss-dsi-aod-hbm-off-command = [

				];
				qcom,mdss-dsi-aod-high-mode-command = [
					39 00 00 40 00 00 04 FF 78 38 02
					15 00 00 40 00 00 02 38 13
					15 00 00 40 00 00 02 19 02
					39 00 00 40 00 00 04 FF 78 38 00
					05 00 00 00 00 00 01 39
				];
				qcom,mdss-dsi-aod-low-mode-command = [
					39 00 00 40 00 00 04 FF 78 38 02
					15 00 00 40 00 00 02 38 23
					15 00 00 40 00 00 02 19 01
					39 00 00 40 00 00 04 FF 78 38 00
					05 00 00 00 00 00 01 39
				];
				qcom,mdss-dsi-lp1-command = [
					//AOD ON
					39 00 00 40 00 00 04 FF 78 38 02
					15 00 00 40 00 00 02 38 13
					15 00 00 40 00 00 02 19 02
					39 00 00 40 00 00 04 FF 78 38 00
					05 00 00 00 00 00 01 39
				];
				qcom,mdss-dsi-nolp-command = [
					//AOD OFF
					39 00 00 40 00 00 04 FF 78 38 00
					05 00 00 40 00 00 01 38
					39 00 00 40 00 00 03 51 00 00
					39 01 00 40 00 00 04 FF 78 38 05
					39 01 00 40 00 00 02 5B 42
					39 00 00 00 00 00 04 FF 78 38 00
				];
				//qcom,mdss-dsi-seed-off-command = [

				//];
				//qcom,mdss-dsi-seed-3-command = [

				//];
				//qcom,mdss-dsi-seed-2-command = [

				//];
				//qcom,mdss-dsi-seed-1-command = [

				//];
				//qcom,mdss-dsi-seed-0-command = [

				//];
				qcom,mdss-dsi-hbm-enter-switch-command = [
					39 00 00 00 00 00 03 51 0D BB
				];
				qcom,mdss-dsi-hbm-exit-switch-command = [
					39 00 00 00 00 00 03 51 0D BB
				];
				qcom,mdss-dsi-osc-clk-mode0-command = [
				];
				qcom,mdss-dsi-osc-clk-mode1-command = [
				];
				qcom,mdss-dsi-ffc-mode0-command = [
					/* osc 121.5 */
					39 00 00 40 00 00 04 FF 78 38 0F
					39 00 00 40 00 00 02 6E 12
					39 00 00 00 00 00 04 FF 78 38 00
				];
				qcom,mdss-dsi-ffc-mode1-command = [
					/* osc 128 */
					39 00 00 40 00 00 04 FF 78 38 0F
					39 00 00 40 00 00 02 6E 13
					39 00 00 00 00 00 04 FF 78 38 00
				];
				qcom,mdss-dsi-timing-switch-command-state = "dsi_lp_mode";
				qcom,mdss-dsi-on-command-state = "dsi_lp_mode";
				qcom,mdss-dsi-panel-info-switch-page-command-state = "dsi_lp_mode";
				qcom,mdss-dsi-default-switch-page-command-state = "dsi_lp_mode";
				qcom,mdss-dsi-off-command-state = "dsi_lp_mode";
				qcom,mdss-dsi-hbm-on-command-state = "dsi_lp_mode";
				qcom,mdss-dsi-hbm-off-command-state = "dsi_lp_mode";
				qcom,mdss-dsi-lhbm-on-command-state = "dsi_hs_mode";
				qcom,mdss-dsi-lhbm-off-command-state = "dsi_hs_mode";
				qcom,mdss-dsi-lhbm-on2-command-state = "dsi_hs_mode";
				qcom,mdss-dsi-lhbm-off2-command-state = "dsi_hs_mode";
				qcom,mdss-dsi-lp1-command-state = "dsi_lp_mode";
				qcom,mdss-dsi-nolp-command-state = "dsi_lp_mode";
				qcom,mdss-dsi-aod-high-mode-command-state = "dsi_lp_mode";
				qcom,mdss-dsi-aod-low-mode-command-state = "dsi_lp_mode";
				qcom,mdss-dsi-osc-clk-mode0-command-state = "dsi_lp_mode";
				qcom,mdss-dsi-osc-clk-mode1-command-state = "dsi_lp_mode";
				qcom,mdss-dsi-ffc-mode0-command-state = "dsi_lp_mode";
				qcom,mdss-dsi-ffc-mode1-command-state = "dsi_lp_mode";
				//qcom,mdss-dsi-seed-0-command-state = "dsi_lp_mode";
				//qcom,mdss-dsi-seed-1-command-state = "dsi_lp_mode";
				//qcom,mdss-dsi-seed-2-command-state = "dsi_lp_mode";
				//qcom,mdss-dsi-seed-3-command-state = "dsi_lp_mode";
				//qcom,mdss-dsi-seed-off-command-state = "dsi_lp_mode";
				qcom,compression-mode = "dsc";
				qcom,mdss-dsc-slice-height = <12>;
				qcom,mdss-dsc-slice-width = <540>;
				qcom,mdss-dsc-slice-per-pkt = <2>;
				qcom,mdss-dsc-bit-per-component = <10>;
				qcom,mdss-dsc-bit-per-pixel = <10>;
				qcom,mdss-dsc-block-prediction-enable;
				qcom,mdss-dsc-version = <0x12>;
			};
		};
	};
};



&dsi_oplus_amber_wxn_ili7838a_1080_2412_dsc_cmd_dvt {
	qcom,panel-supply-entries = <&dsi_panel_oplus_pwr_supply_amber_wxn>;
	qcom,mdss-dsi-panel-controller = <&mdss_dsi0>;
	qcom,mdss-dsi-bl-pmic-control-type = "bl_ctrl_dcs";
	qcom,mdss-dsi-bl-inverted-dbv;
	qcom,mdss-dsi-bl-min-level = <1>;
	qcom,mdss-dsi-bl-max-level = <4095>;
	qcom,mdss-brightness-max-level = <4095>;
	oplus,dsi-bl-normal-max-level = <3515>;
	oplus,dsi-brightness-normal-max-level = <3515>;
	oplus,dsi-brightness-default-level = <2047>;
	/* ofp config */
	oplus,ofp-fp-type = <0x08>;
	oplus,ofp-need-to-wait-data-before-aod-on;
	qcom,platform-te-gpio = <&tlmm 99 0>;
	qcom,platform-reset-gpio = <&tlmm 98 0>;
	qcom,ulps-enabled;
	qcom,dsi-select-clocks = "pll_byte_clk0", "pll_dsi_clk0";
	/* serial num config */
	oplus,dsi-serial-number-enabled;
	oplus,dsi-serial-number-index= <0>;
	oplus,dsi-serial-number-switch-page;
	oplus,dsi-serial-number-multi-reg;
	oplus,dsi-serial-number-multi-regs = [00 01 02 03 04 05 06];
	/* osc */
	oplus,ffc-enabled;
	oplus,ffc-handle;
	oplus,clk-osc-sequence =
		<978000000 121500>,
		<978000000 128000>;
	oplus,dsi-fod-brightness = <36 0xed>,
			<60 0xec>,
			<90 0xeb>,
			<140 0xea>,
			<200 0xe8>,
			<300 0xe4>,
			<458 0xe0>,
			<605 0xdb>,
			<743 0xcf>,
			<912 0xc8>,
			<1062 0xbf>,
			<1187 0xb6>,
			<1393 0xa0>,
			<1611 0x9b>,
			<1787 0x92>,
			<2000 0x8b>,
			<2200 0x80>,
			<2400 0x70>,
			<2600 0x60>,
			<2800 0x50>,
			<3000 0x4A>,
			<3200 0x40>,
			<3400 0x36>,
			<3515 0x2e>;

	qcom,mdss-dsi-display-timings {
		timing@0 {
				qcom,mdss-dsi-panel-phy-timings = [00 21 08 08 19 16 09 08 09 02 04 00 1C 0D];
				qcom,display-topology = <1 1 1>;
				qcom,default-topology-index = <0>;
		};
		timing@1 {
				qcom,mdss-dsi-panel-phy-timings = [00 21 08 08 19 16 09 08 09 02 04 00 1C 0D];
				qcom,display-topology = <1 1 1>;
				qcom,default-topology-index = <0>;
		};
		timing@2 {
				qcom,mdss-dsi-panel-phy-timings = [00 21 08 08 19 16 09 08 09 02 04 00 1C 0D];
				qcom,display-topology = <1 1 1>;
				qcom,default-topology-index = <0>;
		};
	};
};

&dsi_oplus_amber_wxn_ili7838a_1080_2412_dsc_cmd_dvt {
	qcom,panel_voltage_vddi_name = "vddio";
	qcom,panel_voltage_vddi = <0 1800000 1850000 1950000>;
	qcom,panel_voltage_vddr_name = "vddio";
	qcom,panel_voltage_vddr = <1 1800000 1850000 1950000>;
};
